# S6E1A1xC register map
Vendor: Cypress; File version: 2.1
CPU: CM0PLUS r0p1, little endian, no MPU, no FPU, 2 interrupt priority bits
Registers are 32-bit, read-write, reset 0x0 unless marked. A register's access mark holds for its fields unless they carry their own. Offsets are from the block's base; [hi:lo] are bit positions.

## BTIOSEL03 — Base Timer I/O Select
Base 0x40025100
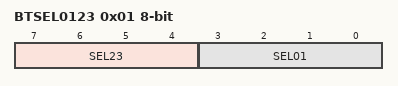
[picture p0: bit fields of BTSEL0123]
0x01 BTSEL0123 8-bit — I/O Select Register [BHW]
  [7:4] SEL23 — I/O select bits for Ch.2/Ch.3
  [3:0] SEL01 — I/O select bits for Ch.0/Ch.1

## SBSSR — Software-based Simultaneous Startup Register
Base 0x40025F00
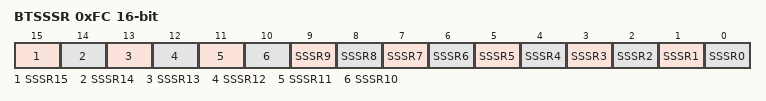
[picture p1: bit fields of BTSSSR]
0xFC BTSSSR 16-bit wo — Software-based Simultaneous Startup Register [BHW]
  [15] SSSR15 — Software-based simultaneous startup bit of Ch.15
  [14] SSSR14 — Software-based simultaneous startup bit of Ch.14
  [13] SSSR13 — Software-based simultaneous startup bit of Ch.13
  [12] SSSR12 — Software-based simultaneous startup bit of Ch.12
  [11] SSSR11 — Software-based simultaneous startup bit of Ch.11
  [10] SSSR10 — Software-based simultaneous startup bit of Ch.10
  [9] SSSR9 — Software-based simultaneous startup bit of Ch.9
  [8] SSSR8 — Software-based simultaneous startup bit of Ch.8
  [7] SSSR7 — Software-based simultaneous startup bit of Ch.7
  [6] SSSR6 — Software-based simultaneous startup bit of Ch.6
  [5] SSSR5 — Software-based simultaneous startup bit of Ch.5
  [4] SSSR4 — Software-based simultaneous startup bit of Ch.4
  [3] SSSR3 — Software-based simultaneous startup bit of Ch.3
  [2] SSSR2 — Software-based simultaneous startup bit of Ch.2
  [1] SSSR1 — Software-based simultaneous startup bit of Ch.1
  [0] SSSR0 — Software-based simultaneous startup bit of Ch.0

## QPRC0 — Quadrature Position/Revolution Counter 0
Base 0x40026000
0x00 QPCR 16-bit — QPRC Position Count Register [HW]
0x04 QRCR 16-bit — QPRC Revolution Count Register [HW]
0x08 QPCCR 16-bit — QPRC Position Counter Compare Register [HW]
0x0C QPRCR 16-bit — QPRC Position and Revolution Counter Compare Register [HW]
0x10 QMPR 16-bit reset 0xFFFF — QPRC Maximum Position Register [HW]
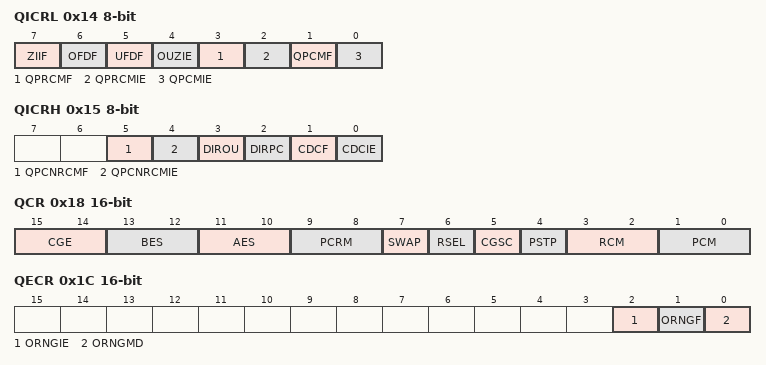
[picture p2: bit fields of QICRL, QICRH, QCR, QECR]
0x14 QICRL 8-bit — Low-Order Bytes of QPRC Interrupt Control Register [BHW]
  [7] ZIIF — Zero index interrupt request flag bit
  [6] OFDF — Overflow interrupt request flag bit
  [5] UFDF — Underflow interrupt request flag bit
  [4] OUZIE — Overflow/underflow or zero index interrupt enable bit
  [3] QPRCMF — PC and RC match interrupt request flag bit
  [2] QPRCMIE — PC and RC match interrupt enable bit
  [1] QPCMF — PC match interrupt request flag bit
  [0] QPCMIE — PC match interrupt enable bit
0x15 QICRH 8-bit — High-Order Bytes of QPRC Interrupt Control Register [BHW]
  [5] QPCNRCMF — PC match and RC match interrupt request flag bit
  [4] QPCNRCMIE — PC match and RC match interrupt enable bit
  [3] DIROU ro — Last position counter flow direction bit
  [2] DIRPC ro — Last position counter direction bit
  [1] CDCF — Count inversion interrupt request flag bit
  [0] CDCIE — Count inversion interrupt enable bit
0x18 QCR 16-bit — High-Order Bytes of QPRC Control Register [BHW]
  [15:14] CGE — Detection edge selection bits
  [13:12] BES — BIN detection edge selection bits
  [11:10] AES — AIN detection edge selection bits
  [9:8] PCRM — Position counter reset mask bits
  [7] SWAP — Swap bit
  [6] RSEL — Register function selection bit
  [5] CGSC — Count clear or gate selection bit
  [4] PSTP — Position counter stop bit
  [3:2] RCM — Revolution counter mode bits
  [1:0] PCM — Position counter mode bits
0x1C QECR 16-bit — QPRC Extension Control Register [BHW]
  [2] ORNGIE — Outrange interrupt enable bit
  [1] ORNGF — Outrange interrupt request flag bit
  [0] ORNGMD — Outrange mode selection bit
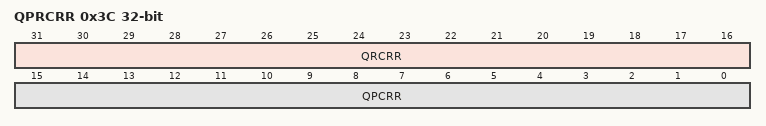
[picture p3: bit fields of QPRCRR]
0x3C QPRCRR ro — Quad Counter Position Rotation Count Register [BHW]
  [31:16] QRCRR — Quad counter rotation count display bit
  [15:0] QPCRR — Quad counter position count display bit

## QPRC0_NF — Quadrature Position/Revolution Counter 0 Noise Filter
Base 0x40026100
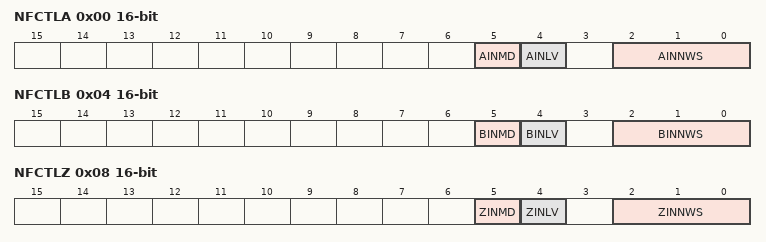
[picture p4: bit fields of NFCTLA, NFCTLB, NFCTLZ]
0x00 NFCTLA 16-bit — AIN Noise Control Register [BHW]
  [5] AINMD — Mask bit
  [4] AINLV — Input invert bit
  [2:0] AINNWS — Noise filter width select bits
0x04 NFCTLB 16-bit — BIN Noise Control Register [BHW]
  [5] BINMD — Mask bit
  [4] BINLV — Input invert bit
  [2:0] BINNWS — Noise filter width select bits
0x08 NFCTLZ 16-bit — ZIN Noise Control Register [BHW]
  [5] ZINMD — Mask bit
  [4] ZINLV — Input invert bit
  [2:0] ZINNWS — Noise filter width select bits
